# DSPIC33FJ16GP101 register map
Vendor: Microchip
Registers are 16-bit, read-write, no defined reset value unless marked. A register's access mark holds for its fields unless they carry their own. Addresses are absolute, and some are shared; only a register's first bit layout is shown; [hi:lo] are bit positions; {n}, {i} and the like mark numbered series.

## SFR
{0x0+2i} WREG{i} (i=0..14) — (power-on value xxxxxxxxxxxxxxxx)
0x1E WREG15 reset 0x800
0x20 SPLIM — (power-on value xxxxxxxxxxxxxxxx)
0x22 ACCAL — (power-on value xxxxxxxxxxxxxxxx)
0x24 ACCAH — (power-on value xxxxxxxxxxxxxxxx)
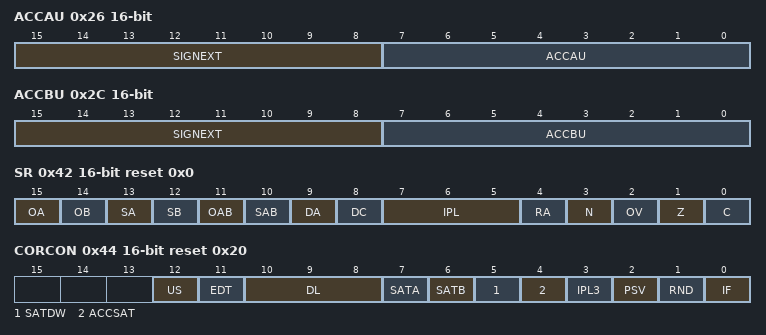
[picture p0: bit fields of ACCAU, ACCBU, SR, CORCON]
0x26 ACCAU — (power-on value 00000000xxxxxxxx)
  [15:8] SIGNEXT ro, [7:0] ACCAU
0x28 ACCBL — (power-on value xxxxxxxxxxxxxxxx)
0x2A ACCBH — (power-on value xxxxxxxxxxxxxxxx)
0x2C ACCBU — (power-on value 00000000xxxxxxxx)
  [15:8] SIGNEXT ro, [7:0] ACCBU
0x2E PCL ro reset 0x0
0x30 PCH ro reset 0x0
  [7:0] PCH
0x32 TBLPAG reset 0x0
  [7:0] TBLPAG
0x34 PSVPAG reset 0x0
  [7:0] PSVPAG
0x36 RCOUNT — (power-on value --xxxxxxxxxxxxxx)
  [13:0] RCOUNT
0x38 DCOUNT — (power-on value --xxxxxxxxxxxxxx)
  [13:0] DCOUNT
0x3A DOSTARTL — (power-on value xxxxxxxxxxxxxxx0)
0x3C DOSTARTH — (power-on value ----------xxxxxx)
  [5:0] DOSTARTH
0x3E DOENDL — (power-on value xxxxxxxxxxxxxxx0)
0x40 DOENDH — (power-on value ----------xxxxxx)
  [5:0] DOENDH
0x42 SR reset 0x0
  [15] OA ro
  [14] OB ro
  [13] SA — (can only be cleared)
  [12] SB — (can only be cleared)
  [11] OAB ro
  [10] SAB — (can only be cleared)
  [9] DA ro
  [8] DC
  [7:5] IPL
  [4] RA ro
  [3] N
  [2] OV
  [1] Z
  [0] C
0x44 CORCON reset 0x20
  [12] US
  [11] EDT wo
  [10:8] DL ro
  [7] SATA
  [6] SATB
  [5] SATDW
  [4] ACCSAT
  [3] IPL3 — (can only be cleared)
  [2] PSV
  [1] RND
  [0] IF
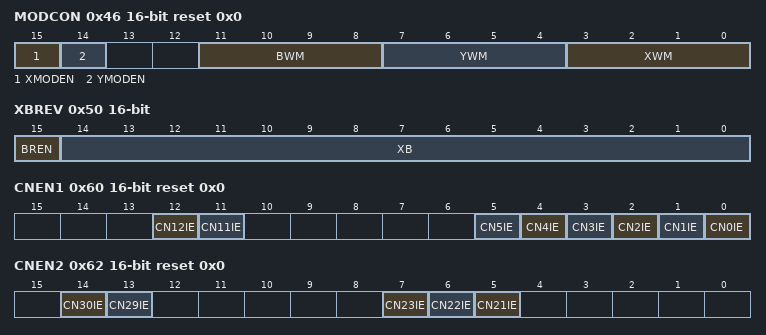
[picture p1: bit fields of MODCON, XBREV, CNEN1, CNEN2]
0x46 MODCON reset 0x0
  [15] XMODEN, [14] YMODEN, [11:8] BWM, [7:4] YWM, [3:0] XWM
0x48 XMODSRT — (power-on value xxxxxxxxxxxxxxx0)
  [15:0] XS
0x4A XMODEND — (power-on value xxxxxxxxxxxxxxx1)
  [15:0] XE
0x4C YMODSRT — (power-on value xxxxxxxxxxxxxxx0)
  [15:0] YS
0x4E YMODEND — (power-on value xxxxxxxxxxxxxxx1)
  [15:0] YE
0x50 XBREV — (power-on value 0xxxxxxxxxxxxxxx)
  [15] BREN, [14:0] XB
0x52 DISICNT — (power-on value --xxxxxxxxxxxxxx)
  [13:0] DISICNT
0x60 CNEN1 reset 0x0
  [12] CN12IE, [11] CN11IE, [n] CN{n}IE (n=0..5)
0x62 CNEN2 reset 0x0
  [14] CN30IE, [13] CN29IE, [7] CN23IE, [6] CN22IE, [5] CN21IE
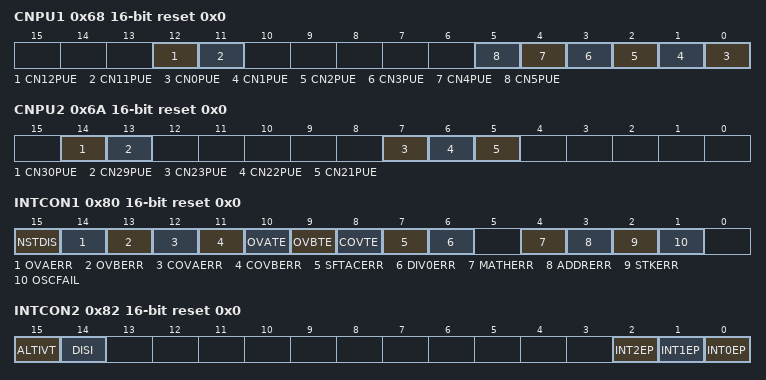
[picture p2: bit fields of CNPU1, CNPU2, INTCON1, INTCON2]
0x68 CNPU1 reset 0x0
  [12] CN12PUE, [11] CN11PUE, [n] CN{n}PUE (n=0..5)
0x6A CNPU2 reset 0x0
  [14] CN30PUE, [13] CN29PUE, [7] CN23PUE, [6] CN22PUE, [5] CN21PUE
0x80 INTCON1 reset 0x0
  [15] NSTDIS, [14] OVAERR, [13] OVBERR, [12] COVAERR, [11] COVBERR, [10] OVATE, [9] OVBTE, [8] COVTE, [7] SFTACERR, [6] DIV0ERR, [4] MATHERR, [3] ADDRERR, [2] STKERR, [1] OSCFAIL
0x82 INTCON2 reset 0x0
  [15] ALTIVT, [14] DISI ro, [2] INT2EP, [1] INT1EP, [0] INT0EP
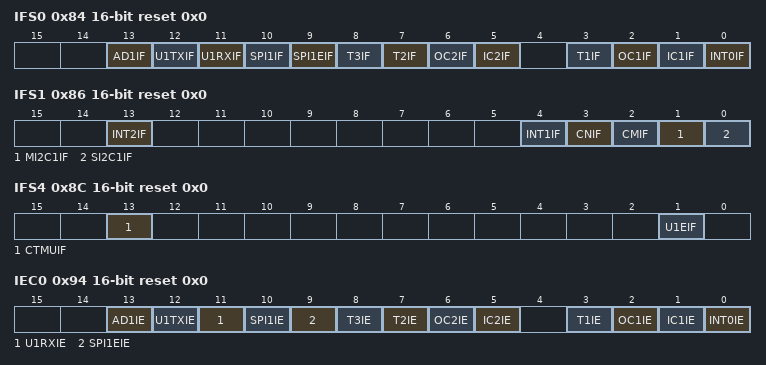
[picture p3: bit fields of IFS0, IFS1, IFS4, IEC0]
0x84 IFS0 reset 0x0
  [13] AD1IF, [12] U1TXIF, [11] U1RXIF, [10] SPI1IF, [9] SPI1EIF, [8] T3IF, [7] T2IF, [6] OC2IF, [5] IC2IF, [3] T1IF, [2] OC1IF, [1] IC1IF, [0] INT0IF
0x86 IFS1 reset 0x0
  [13] INT2IF, [4] INT1IF, [3] CNIF, [2] CMIF, [1] MI2C1IF, [0] SI2C1IF
0x88 IFS2 reset 0x0
  [5] IC3IF
0x8A IFS3 reset 0x0
  [14] RTCIF
0x8C IFS4 reset 0x0
  [13] CTMUIF, [1] U1EIF
0x94 IEC0 reset 0x0
  [13] AD1IE, [12] U1TXIE, [11] U1RXIE, [10] SPI1IE, [9] SPI1EIE, [8] T3IE, [7] T2IE, [6] OC2IE, [5] IC2IE, [3] T1IE, [2] OC1IE, [1] IC1IE, [0] INT0IE
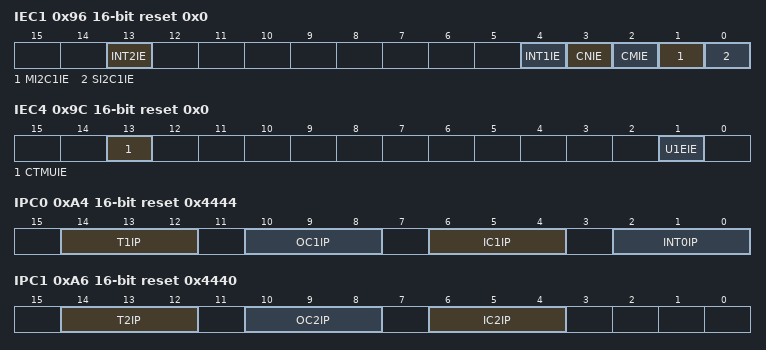
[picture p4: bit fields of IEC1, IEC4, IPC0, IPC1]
0x96 IEC1 reset 0x0
  [13] INT2IE, [4] INT1IE, [3] CNIE, [2] CMIE, [1] MI2C1IE, [0] SI2C1IE
0x98 IEC2 reset 0x0
  [5] IC3IE
0x9A IEC3 reset 0x0
  [14] RTCIE
0x9C IEC4 reset 0x0
  [13] CTMUIE, [1] U1EIE
0xA4 IPC0 reset 0x4444
  [14:12] T1IP, [10:8] OC1IP, [6:4] IC1IP, [2:0] INT0IP
0xA6 IPC1 reset 0x4440
  [14:12] T2IP, [10:8] OC2IP, [6:4] IC2IP
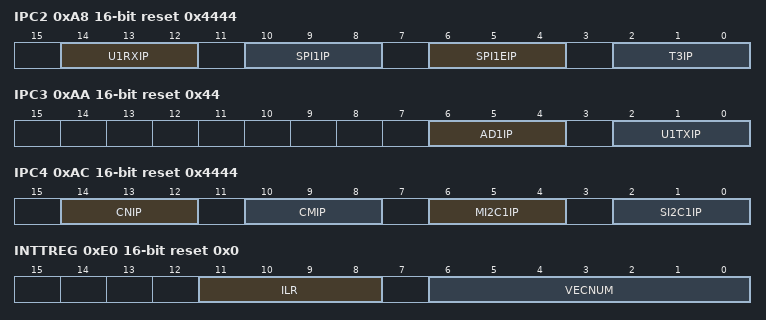
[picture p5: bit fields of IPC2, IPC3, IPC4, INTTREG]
0xA8 IPC2 reset 0x4444
  [14:12] U1RXIP, [10:8] SPI1IP, [6:4] SPI1EIP, [2:0] T3IP
0xAA IPC3 reset 0x44
  [6:4] AD1IP, [2:0] U1TXIP
0xAC IPC4 reset 0x4444
  [14:12] CNIP, [10:8] CMIP, [6:4] MI2C1IP, [2:0] SI2C1IP
0xAE IPC5 reset 0x4
  [2:0] INT1IP
0xB2 IPC7 reset 0x40
  [6:4] INT2IP
0xB6 IPC9 reset 0x40
  [6:4] IC3IP
0xC2 IPC15 reset 0x400
  [10:8] RTCIP
0xC4 IPC16 reset 0x40
  [6:4] U1EIP
0xCA IPC19 reset 0x40
  [6:4] CTMUIP
0xE0 INTTREG reset 0x0
  [11:8] ILR ro, [6:0] VECNUM
0x100 TMR1 — (power-on value xxxxxxxxxxxxxxxx)
0x102 PR1 reset 0xFFFF
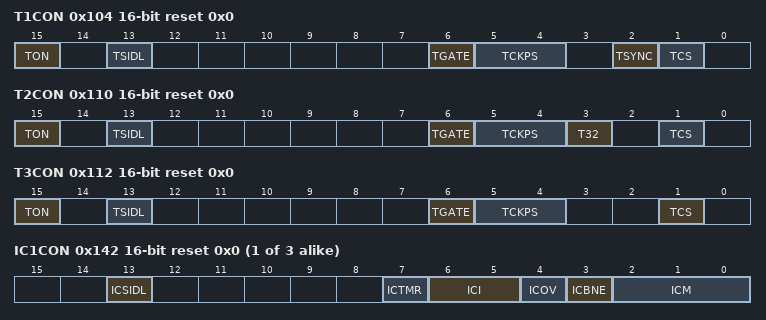
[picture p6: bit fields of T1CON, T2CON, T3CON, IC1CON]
0x104 T1CON reset 0x0
  [15] TON, [13] TSIDL, [6] TGATE, [5:4] TCKPS, [2] TSYNC, [1] TCS
0x106 TMR2 — (power-on value xxxxxxxxxxxxxxxx)
0x108 TMR3HLD — (power-on value xxxxxxxxxxxxxxxx)
0x10A TMR3 — (power-on value xxxxxxxxxxxxxxxx)
0x10C PR2 reset 0xFFFF
0x10E PR3 reset 0xFFFF
0x110 T2CON reset 0x0
  [15] TON, [13] TSIDL, [6] TGATE, [5:4] TCKPS, [3] T32, [1] TCS
0x112 T3CON reset 0x0
  [15] TON, [13] TSIDL, [6] TGATE, [5:4] TCKPS, [1] TCS
{0x13C+4i} IC{i}BUF ro (i=1..3) — (power-on value xxxxxxxxxxxxxxxx)
{0x13E+4i} IC{i}CON reset 0x0 (i=1..3)
  [13] ICSIDL, [7] ICTMR, [6:5] ICI, [4] ICOV ro, [3] ICBNE ro, [2:0] ICM
0x180 OC1RS — (power-on value xxxxxxxxxxxxxxxx)
0x182 OC1R — (power-on value xxxxxxxxxxxxxxxx)
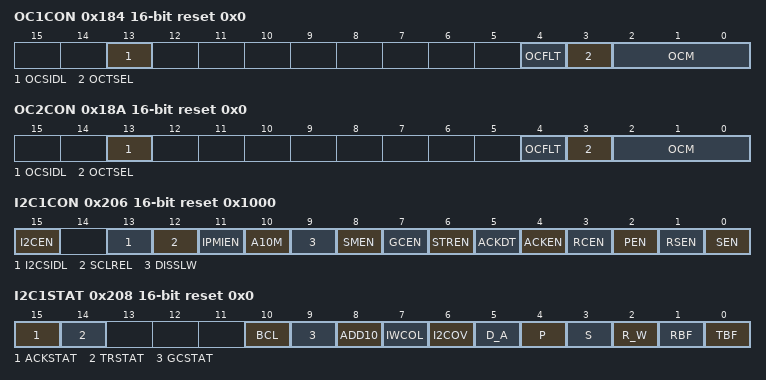
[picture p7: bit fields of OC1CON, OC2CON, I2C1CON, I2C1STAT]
0x184 OC1CON reset 0x0
  [13] OCSIDL, [4] OCFLT ro, [3] OCTSEL, [2:0] OCM
0x186 OC2RS — (power-on value xxxxxxxxxxxxxxxx)
0x188 OC2R — (power-on value xxxxxxxxxxxxxxxx)
0x18A OC2CON reset 0x0
  [13] OCSIDL, [4] OCFLT ro, [3] OCTSEL, [2:0] OCM
0x200 I2C1RCV ro reset 0x0
  [7:0] I2CRCV
0x202 I2C1TRN wo reset 0xFF
  [7:0] I2CTRN
0x204 I2C1BRG reset 0x0
  [8:0] I2CBRG
0x206 I2C1CON reset 0x1000
  [15] I2CEN, [13] I2CSIDL, [12] SCLREL, [11] IPMIEN, [10] A10M, [9] DISSLW, [8] SMEN, [7] GCEN, [6] STREN, [5] ACKDT, [4] ACKEN, [3] RCEN, [2] PEN, [1] RSEN, [0] SEN
0x208 I2C1STAT reset 0x0
  [15] ACKSTAT ro
  [14] TRSTAT ro
  [10] BCL — (can only be cleared)
  [9] GCSTAT ro
  [8] ADD10 ro
  [7] IWCOL — (can only be cleared)
  [6] I2COV — (can only be cleared)
  [5] D_A ro
  [4] P — (can only be cleared)
  [3] S — (can only be cleared)
  [2] R_W ro
  [1] RBF ro
  [0] TBF ro
0x20A I2C1ADD reset 0x0
  [9:0] I2CADD
0x20C I2C1MSK reset 0x0
  [9:0] AMSK
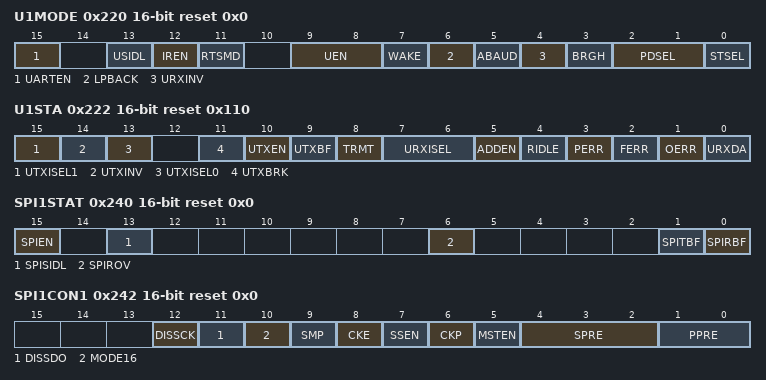
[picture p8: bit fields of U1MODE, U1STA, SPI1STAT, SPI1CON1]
0x220 U1MODE reset 0x0
  [15] UARTEN, [13] USIDL, [12] IREN, [11] RTSMD, [9:8] UEN, [7] WAKE, [6] LPBACK, [5] ABAUD, [4] URXINV, [3] BRGH, [2:1] PDSEL, [0] STSEL
0x222 U1STA reset 0x110
  [15] UTXISEL1
  [14] UTXINV
  [13] UTXISEL0
  [11] UTXBRK
  [10] UTXEN
  [9] UTXBF ro
  [8] TRMT ro
  [7:6] URXISEL
  [5] ADDEN
  [4] RIDLE ro
  [3] PERR ro
  [2] FERR ro
  [1] OERR — (can only be cleared)
  [0] URXDA ro
0x224 U1TXREG wo — (power-on value -------xxxxxxxxx)
  [8:0] U1TXREG
0x226 U1RXREG ro reset 0x0
  [8:0] U1RXREG
0x228 U1BRG reset 0x0
  [15:0] BRG
0x240 SPI1STAT reset 0x0
  [15] SPIEN
  [13] SPISIDL
  [6] SPIROV — (can only be cleared)
  [1] SPITBF ro
  [0] SPIRBF ro
0x242 SPI1CON1 reset 0x0
  [12] DISSCK, [11] DISSDO, [10] MODE16, [9] SMP, [8] CKE, [7] SSEN, [6] CKP, [5] MSTEN, [4:2] SPRE, [1:0] PPRE
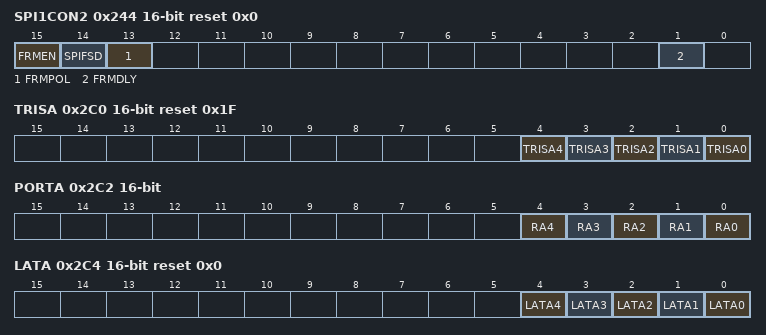
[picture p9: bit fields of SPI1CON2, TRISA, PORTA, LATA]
0x244 SPI1CON2 reset 0x0
  [15] FRMEN, [14] SPIFSD, [13] FRMPOL, [1] FRMDLY
0x248 SPI1BUF reset 0x0
0x2C0 TRISA reset 0x1F
  [n] TRISA{n} (n=0..4)
0x2C2 PORTA — (power-on value -----------xxxxx)
  [n] RA{n} (n=0..4)
0x2C4 LATA reset 0x0
  [n] LATA{n} (n=0..4)
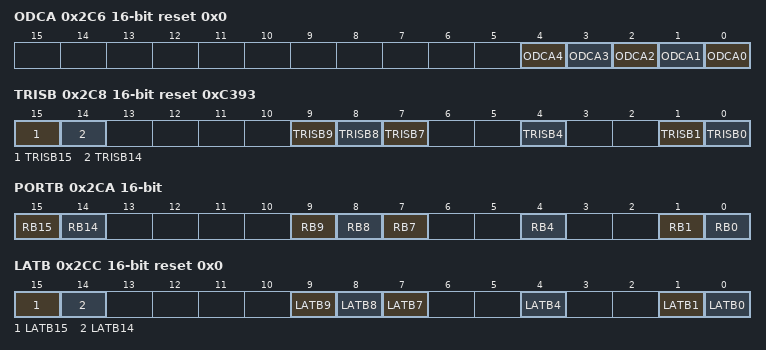
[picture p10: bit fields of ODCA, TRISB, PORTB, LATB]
0x2C6 ODCA reset 0x0
  [n] ODCA{n} (n=0..4)
0x2C8 TRISB reset 0xC393
  [15] TRISB15, [14] TRISB14, [9] TRISB9, [8] TRISB8, [7] TRISB7, [4] TRISB4, [1] TRISB1, [0] TRISB0
0x2CA PORTB — (power-on value xx----xxx--x--xx)
  [15] RB15, [14] RB14, [9] RB9, [8] RB8, [7] RB7, [4] RB4, [1] RB1, [0] RB0
0x2CC LATB reset 0x0
  [15] LATB15, [14] LATB14, [9] LATB9, [8] LATB8, [7] LATB7, [4] LATB4, [1] LATB1, [0] LATB0
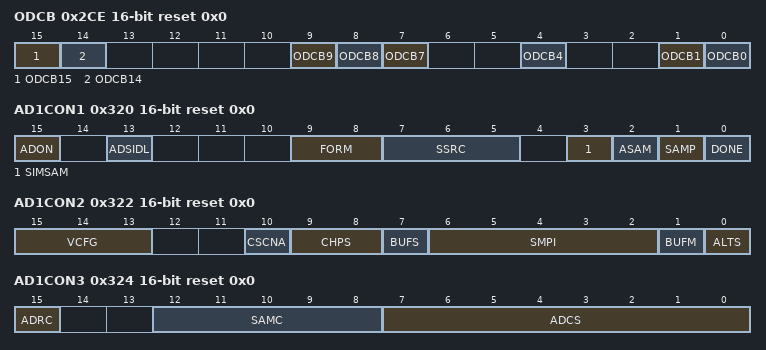
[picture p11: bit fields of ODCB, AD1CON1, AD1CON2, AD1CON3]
0x2CE ODCB reset 0x0
  [15] ODCB15, [14] ODCB14, [9] ODCB9, [8] ODCB8, [7] ODCB7, [4] ODCB4, [1] ODCB1, [0] ODCB0
0x2FC PADCFG1 reset 0x0
  [1] RTSECSEL
{0x300+2i} ADC1BUF{i} ro (i=0..9) — (power-on value xxxxxxxxxxxxxxxx)
  [11:0] ADC1BUF{i}
0x314 ADC1BUFA ro — (power-on value xxxxxxxxxxxxxxxx)
  [11:0] ADC1BUFA
0x316 ADC1BUFB ro — (power-on value xxxxxxxxxxxxxxxx)
  [11:0] ADC1BUFB
0x318 ADC1BUFC ro — (power-on value xxxxxxxxxxxxxxxx)
  [11:0] ADC1BUFC
0x31A ADC1BUFD ro — (power-on value xxxxxxxxxxxxxxxx)
  [11:0] ADC1BUFD
0x31C ADC1BUFE ro — (power-on value xxxxxxxxxxxxxxxx)
  [11:0] ADC1BUFE
0x31E ADC1BUFF ro — (power-on value xxxxxxxxxxxxxxxx)
  [11:0] ADC1BUFF
0x320 AD1CON1 reset 0x0
  [15] ADON
  [13] ADSIDL
  [9:8] FORM
  [7:5] SSRC
  [3] SIMSAM
  [2] ASAM
  [1] SAMP
  [0] DONE — (can only be cleared)
0x322 AD1CON2 reset 0x0
  [15:13] VCFG, [10] CSCNA, [9:8] CHPS, [7] BUFS ro, [6:2] SMPI, [1] BUFM, [0] ALTS
0x324 AD1CON3 reset 0x0
  [15] ADRC, [12:8] SAMC, [7:0] ADCS
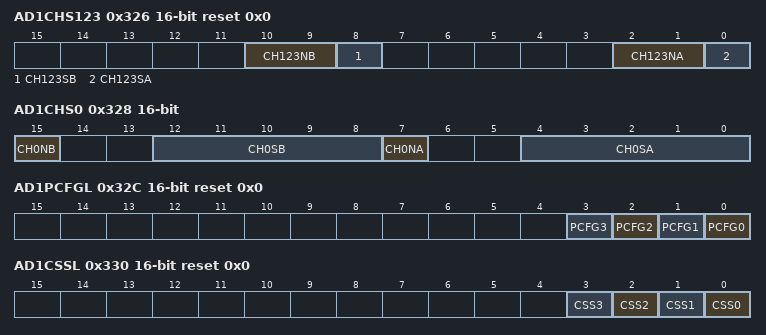
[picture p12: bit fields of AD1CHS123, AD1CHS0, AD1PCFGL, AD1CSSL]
0x326 AD1CHS123 reset 0x0
  [10:9] CH123NB, [8] CH123SB, [2:1] CH123NA, [0] CH123SA
0x328 AD1CHS0 — (power-on value 0--xxxxx0--xxxxx)
  [15] CH0NB, [12:8] CH0SB, [7] CH0NA, [4:0] CH0SA
0x32C AD1PCFGL reset 0x0
  [n] PCFG{n} (n=0..3)
0x330 AD1CSSL reset 0x0
  [n] CSS{n} (n=0..3)
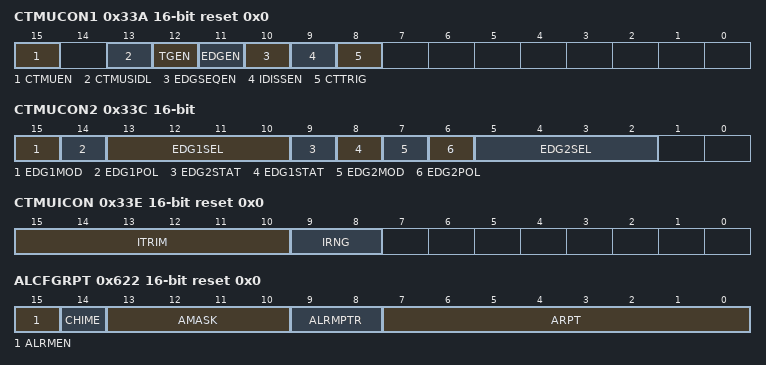
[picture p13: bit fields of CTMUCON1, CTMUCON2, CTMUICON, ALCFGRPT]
0x33A CTMUCON1 reset 0x0
  [15] CTMUEN, [13] CTMUSIDL, [12] TGEN, [11] EDGEN, [10] EDGSEQEN, [9] IDISSEN, [8] CTTRIG
0x33C CTMUCON2 — (power-on value 00xxxx0000xxxx--)
  [15] EDG1MOD, [14] EDG1POL, [13:10] EDG1SEL, [9] EDG2STAT, [8] EDG1STAT, [7] EDG2MOD, [6] EDG2POL, [5:2] EDG2SEL
0x33E CTMUICON reset 0x0
  [15:10] ITRIM, [9:8] IRNG
0x620 ALRMVAL reset 0x0
0x622 ALCFGRPT reset 0x0
  [15] ALRMEN, [14] CHIME, [13:10] AMASK, [9:8] ALRMPTR, [7:0] ARPT
0x624 RTCVAL reset 0x0
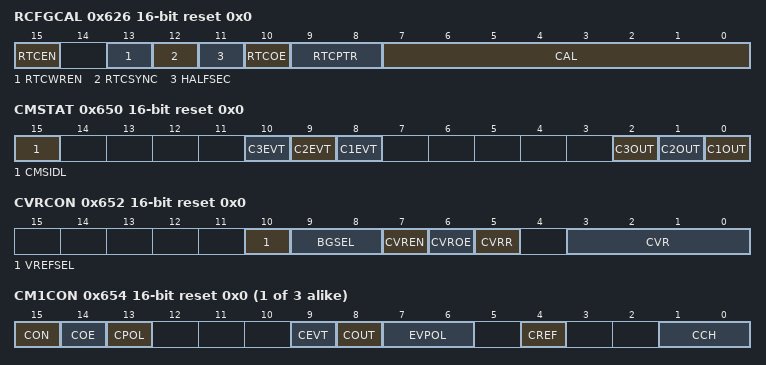
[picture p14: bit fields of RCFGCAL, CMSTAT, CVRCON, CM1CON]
0x626 RCFGCAL reset 0x0
  [15] RTCEN, [13] RTCWREN, [12] RTCSYNC, [11] HALFSEC, [10] RTCOE, [9:8] RTCPTR, [7:0] CAL
0x650 CMSTAT reset 0x0
  [15] CMSIDL, [10] C3EVT ro, [9] C2EVT ro, [8] C1EVT ro, [2] C3OUT ro, [1] C2OUT ro, [0] C1OUT ro
0x652 CVRCON reset 0x0
  [10] VREFSEL, [9:8] BGSEL, [7] CVREN, [6] CVROE, [5] CVRR, [3:0] CVR
{0x64C+8i} CM{i}CON reset 0x0 (i=1..3)
  [15] CON, [14] COE, [13] CPOL, [9] CEVT, [8] COUT ro, [7:6] EVPOL, [4] CREF, [1:0] CCH
{0x64E+8i} CM{i}MSKSRC (i=1..3) — (power-on value ----xxxxxxxxxxxx)
  [11:8] SELSRCC, [7:4] SELSRCB, [3:0] SELSRCA
{0x650+8i} CM{i}MSKCON (i=1..3) — (power-on value x-xxxxxxxxxxxxxx)
  [15] HLMS, [13] OCEN, [12] OCNEN, [11] OBEN, [10] OBNEN, [9] OAEN, [8] OANEN, [7] NAGS, [6] PAGS, [5] ACEN, [4] ACNEN, [3] ABEN, [2] ABNEN, [1] AAEN, [0] AANEN
{0x652+8i} CM{i}FLTR (i=1..3) — (power-on value ---------xxxxxxx)
  [6:4] CFSEL, [3] CFLTREN, [2:0] CFDIV
0x680 RPINR0 reset 0x1F00
  [12:8] INT1R
0x682 RPINR1 reset 0x1F
  [4:0] INT2R
0x686 RPINR3 reset 0x1F1F
  [12:8] T3CKR, [4:0] T2CKR
0x68E RPINR7 reset 0x1F1F
  [12:8] IC2R, [4:0] IC1R
0x690 RPINR8 reset 0x1F
  [4:0] IC3R
0x696 RPINR11 — (power-on value -----------xxxxx)
  [4:0] OCFAR
0x6A4 RPINR18 reset 0x1F1F
  [12:8] U1CTSR, [4:0] U1RXR
0x6AA RPINR21 reset 0x1F
  [4:0] SS1R
0x6C0 RPOR0 reset 0x0
  [12:8] RP1R, [4:0] RP0R
0x6C4 RPOR2 reset 0x0
  [4:0] RP4R
0x6C6 RPOR3 reset 0x0
  [12:8] RP7R
0x6C8 RPOR4 reset 0x0
  [12:8] RP9R, [4:0] RP8R
0x6CE RPOR7 reset 0x0
  [12:8] RP15R, [4:0] RP14R
0x740 RCON reset 0x3
  [15] TRAPR, [14] IOPUWR, [9] CM, [8] VREGS, [7] EXTR, [6] SWR, [5] SWDTEN, [4] WDTO, [3] SLEEP, [2] IDLE, [1] BOR, [0] POR
0x742 OSCCON — (power-on value -000-yyy000-0-x0)
  [14:12] COSC ro
  [10:8] NOSC
  [7] CLKLOCK
  [6] IOLOCK
  [5] LOCK ro
  [3] CF — (can only be cleared)
  [1] LPOSCEN
  [0] OSWEN
0x744 CLKDIV reset 0x3000
  [15] ROI, [14:12] DOZE, [11] DOZEN, [10:8] FRCDIV
0x748 OSCTUN reset 0x0
  [5:0] TUN
0x760 NVMCON reset 0x0
  [15] WR — (can only be set)
  [14] WREN
  [13] WRERR
  [6] ERASE
  [3:0] NVMOP
0x766 NVMKEY wo reset 0x0
  [7:0] NVMKEY
0x770 PMD1 reset 0x0
  [13] T3MD, [12] T2MD, [11] T1MD, [7] I2C1MD, [5] U1MD, [3] SPI1MD, [0] AD1MD
0x772 PMD2 — (power-on value -----x00------00)
  [10] IC3MD, [9] IC2MD, [8] IC1MD, [1] OC2MD, [0] OC1MD
0x774 PMD3 — (power-on value -----xx---------)
  [10] CMPMD, [9] RTCCMD
0x776 PMD4 — (power-on value -------------x--)
  [2] CTMUMD
